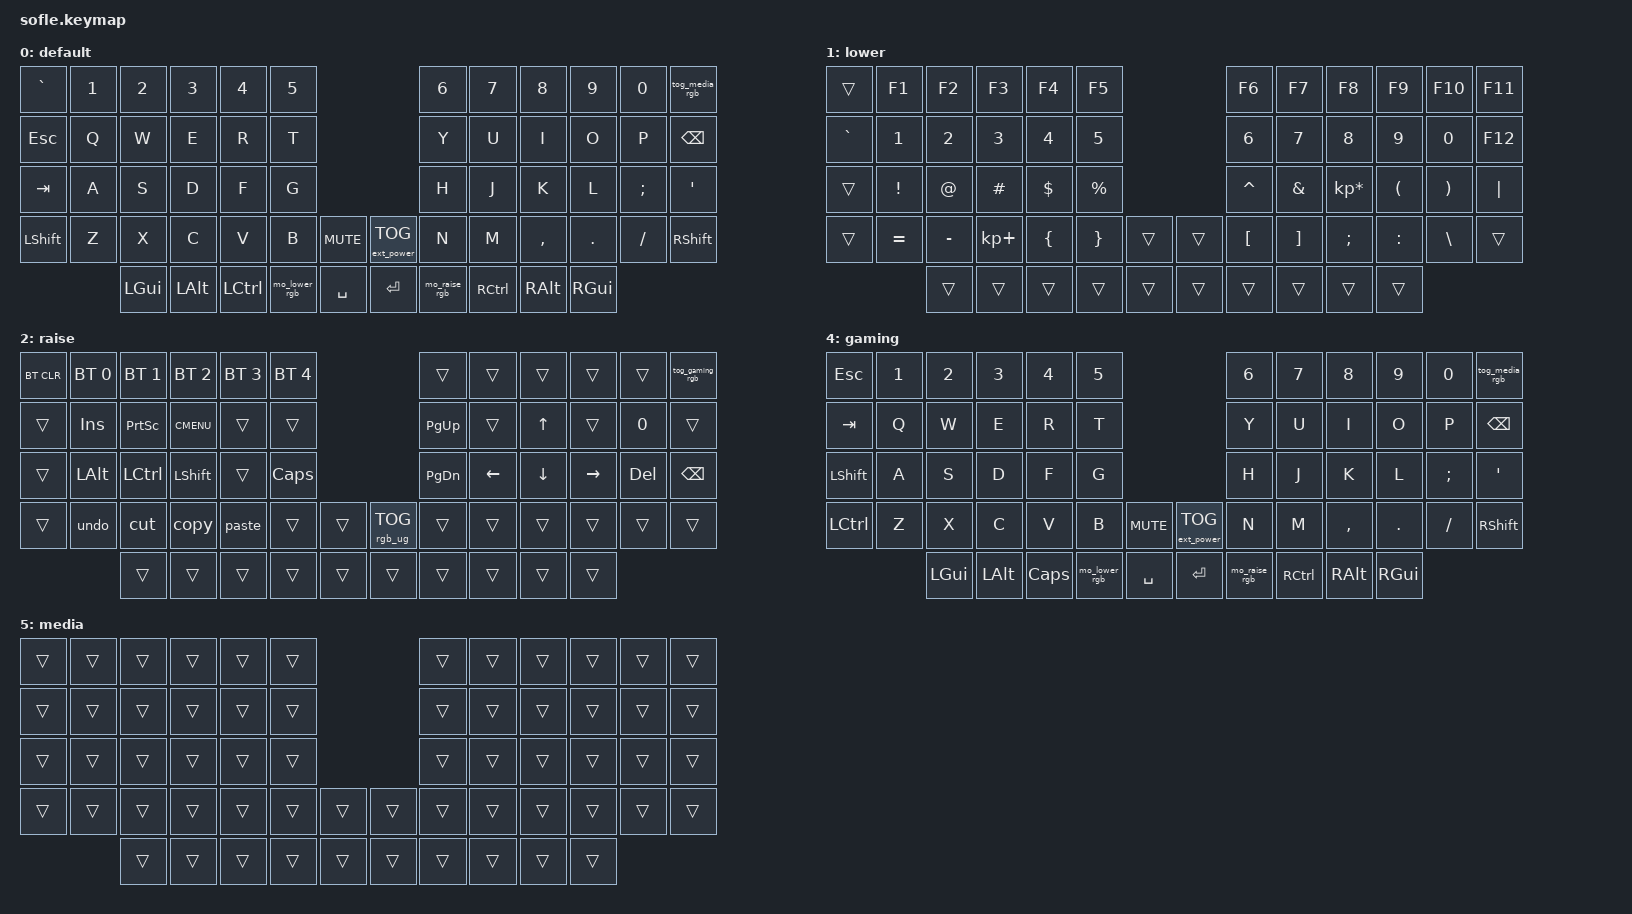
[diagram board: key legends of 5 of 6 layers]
/*
 * Copyright (c) 2020 The ZMK Contributors
 * SPDX-License-Identifier: MIT
 */

/* ===== Includes ===== */
#include <behaviors.dtsi>
#include <dt-bindings/zmk/keys.h>
#include <dt-bindings/zmk/bt.h>
#include <dt-bindings/zmk/ext_power.h>
#include <dt-bindings/zmk/rgb.h>
#include <dt-bindings/led/led.h>

/* ===== Behaviors ===== */
/ {
    macros {
        // Macro: Momentary LOWER layer with RGB hue shift
        mo_lower_rgb: mo_lower_rgb {
            compatible = "zmk,behavior-macro";
            #binding-cells = <0>;
            wait-ms = <0>;
            tap-ms = <0>;
            bindings
                = <&macro_press &mo 1>
                , <&macro_tap &rgb_ug RGB_HUI>  // Single hue shift on press
                , <&macro_pause_for_release>
                , <&macro_release &mo 1>
                , <&macro_tap &rgb_ug RGB_HUD>  // Single hue shift back on release
                ;
        };
        
        // Macro: Momentary RAISE layer with RGB hue shift
        mo_raise_rgb: mo_raise_rgb {
            compatible = "zmk,behavior-macro";
            #binding-cells = <0>;
            wait-ms = <0>;
            tap-ms = <0>;
            bindings
                = <&macro_press &mo 2>
                , <&macro_tap &rgb_ug RGB_HUD>  // Single hue shift on press
                , <&macro_pause_for_release>
                , <&macro_release &mo 2>
                , <&macro_tap &rgb_ug RGB_HUI>  // Single hue shift back on release
                ;
        };
        
        // Macro: Toggle GAMING layer with green RGB color
        // Sets green when entering gaming mode, returns to previous color when exiting
        tog_gaming_rgb: tog_gaming_rgb {
            compatible = "zmk,behavior-macro";
            #binding-cells = <0>;
            wait-ms = <0>;
            tap-ms = <0>;
            bindings
                = <&macro_tap &tog 4>
                , <&macro_tap &rgb_ug RGB_COLOR_HSB(120,100,50)>  // Set green color (120° hue, full saturation, medium brightness)
                ;
        };
        
        // Macro: ADJUST layer with RGB shift (double hue down when active)
        mo_adjust_rgb: mo_adjust_rgb {
            compatible = "zmk,behavior-macro";
            #binding-cells = <0>;
            wait-ms = <0>;
            tap-ms = <0>;
            bindings
                = <&macro_press &mo 3>
                , <&macro_tap &rgb_ug RGB_HUD &rgb_ug RGB_HUD>  // Double hue down shift on press
                , <&macro_pause_for_release>
                , <&macro_release &mo 3>
                , <&macro_tap &rgb_ug RGB_HUI &rgb_ug RGB_HUI>  // Double hue up shift back on release
                ;
        };
        
        // Macro: Toggle MEDIA layer without RGB interference
        // This prevents color shifts from getting stuck when toggling media mode
        tog_media_rgb: tog_media_rgb {
            compatible = "zmk,behavior-macro";
            #binding-cells = <0>;
            wait-ms = <0>;
            tap-ms = <0>;
            bindings
                = <&macro_tap &tog 5>  // Toggle MEDIA layer (no RGB shift to avoid interference)
                ;
        };
        
        // Macro: Undo (Ctrl+Z)
        undo: undo {
            compatible = "zmk,behavior-macro";
            #binding-cells = <0>;
            wait-ms = <30>;
            tap-ms = <30>;
            bindings = <&macro_press &kp LCTRL>, <&macro_tap &kp Z>, <&macro_release &kp LCTRL>;
        };
        
        // Macro: Cut (Ctrl+X)
        cut: cut {
            compatible = "zmk,behavior-macro";
            #binding-cells = <0>;
            wait-ms = <30>;
            tap-ms = <30>;
            bindings = <&macro_press &kp LCTRL>, <&macro_tap &kp X>, <&macro_release &kp LCTRL>;
        };
        
        // Macro: Copy (Ctrl+C)
        copy: copy {
            compatible = "zmk,behavior-macro";
            #binding-cells = <0>;
            wait-ms = <30>;
            tap-ms = <30>;
            bindings = <&macro_press &kp LCTRL>, <&macro_tap &kp C>, <&macro_release &kp LCTRL>;
        };
        
        // Macro: Paste (Ctrl+V)
        paste: paste {
            compatible = "zmk,behavior-macro";
            #binding-cells = <0>;
            wait-ms = <30>;
            tap-ms = <30>;
            bindings = <&macro_press &kp LCTRL>, <&macro_tap &kp V>, <&macro_release &kp LCTRL>;
        };
        
        // Macro: Track Previous (requires 5 encoder ticks for one skip)
        track_prev: track_prev {
            compatible = "zmk,behavior-macro";
            #binding-cells = <0>;
            wait-ms = <0>;
            tap-ms = <0>;
            bindings = <&kp C_PREV>, <&kp C_PREV>, <&kp C_PREV>, <&kp C_PREV>, <&kp C_PREV>;
        };
        
        // Macro: Track Next (requires 5 encoder ticks for one skip)
        track_next: track_next {
            compatible = "zmk,behavior-macro";
            #binding-cells = <0>;
            wait-ms = <0>;
            tap-ms = <0>;
            bindings = <&kp C_NEXT>, <&kp C_NEXT>, <&kp C_NEXT>, <&kp C_NEXT>, <&kp C_NEXT>;
        };
    };
};

/* ===== Layer IDs ===== */
#define BASE    0
#define LOWER   1
#define RAISE   2
#define ADJUST  3
#define GAMING  4
#define MEDIA   5   /* Media control layer for encoders */

/* ===== Readability Macros ===== */
#define TR            &trans
#define NO            &none
#define MO_LOWER      &mo_lower_rgb   /* Momentary LOWER with RGB hue shift */
#define MO_RAISE      &mo_raise_rgb   /* Momentary RAISE with RGB hue shift */
#define TG_GAMING     &tog_gaming_rgb /* Toggle GAMING with RGB hue shift */
#define TG_MEDIA      &tog_media_rgb  /* Toggle MEDIA encoder layer */
// Standard encoder bindings - 1:1 response with EC11 encoders (20 pulses per rotation)
#define SENS_BINDINGS &inc_dec_kp LEFT RIGHT &inc_dec_kp DOWN UP  // Left encoder: horizontal (1:1), Right encoder: vertical (1:1, inverted for natural scroll)
#define MEDIA_SENS    &inc_dec_kp C_VOL_DN C_VOL_UP &inc_dec_kp C_PREV C_NEXT  // Left encoder: volume (1:1), Right encoder: track skip (1:1 per tick, but requires 5 ticks for intentional skip)

/* ===== RGB Layer Colors ===== */
// These macros shift RGB hue when layers are activated:
// Base layer:   Default RGB color (neutral)
// Lower layer:  Hue +2 steps (slight shift)
// Raise layer:  Hue +4 steps (different shift)
// Gaming layer: Hue +6 steps (distinct shift)
// Note: Adjust layer activates with LOWER+RAISE, so it inherits their combined shifts

/*
 * Temporarily here because nice nano v2 spi is not defined on ZMK Yet
 * Source: https://github.com/zmkfirmware/zmk/blob/main/app/boards/shields/reviung41/boards/nice_nano.overlay
 * GitHub Issue: https://github.com/zmkfirmware/zmk/issues/885
 */

/* ===== SPI / WS2812 Underglow ===== */
&pinctrl {
    spi3_default: spi3_default {
        group1 { psels = <NRF_PSEL(SPIM_MOSI, 0, 8)>; };
    };
    spi3_sleep: spi3_sleep {
        group1 {
            psels = <NRF_PSEL(SPIM_MOSI, 0, 8)>;
            low-power-enable;
        };
    };
};

&sensors {
    left_config {
        triggers-per-rotation = <50>;  // Doubled for immediate response (2 pulses per detent)
    };

    right_config {
        triggers-per-rotation = <50>;  // Doubled for immediate response (2 pulses per detent)
    };
};

&spi3 {
    compatible = "nordic,nrf-spim";
    status = "okay";
    pinctrl-0 = <&spi3_default>;
    pinctrl-1 = <&spi3_sleep>;
    pinctrl-names = "default", "sleep";

    led_strip: ws2812@0 {
        compatible = "worldsemi,ws2812-spi";
        label = "WS2812";

        /* SPI */
        reg = <0>; /* ignored, but necessary for SPI bindings */
        spi-max-frequency = <4000000>;

        /* WS2812 */
        chain-length   = <30>;
        spi-one-frame  = <0x70>;
        spi-zero-frame = <0x40>;
        color-mapping  = <LED_COLOR_ID_GREEN LED_COLOR_ID_RED LED_COLOR_ID_BLUE>;
    };
};

 / {
    chosen { zmk,underglow = &led_strip; };
 };

/* ===== Conditional Layers ===== */
 / {
    conditional_layers {
        compatible = "zmk,conditional-layers";
        adjust_layer {
            if-layers  = <LOWER RAISE>;
            then-layer = <ADJUST>;
        };
    };

    /* ===== Keymap ===== */
    keymap {
        compatible = "zmk,keymap";

        /* ---------- BASE (default) ---------- */
        default_layer {
            label = "default";
            // ┌──────┬─────┬─────┬─────┬─────┬─────┐                         ┌─────┬─────┬─────┬─────┬─────┬────────┐
            // │  `   │  1  │  2  │  3  │  4  │  5  │                         │  6  │  7  │  8  │  9  │  0  │MD_TOG  │  <-- above BKSP
            // │ ESC  │  Q  │  W  │  E  │  R  │  T  │                         │  Y  │  U  │  I  │  O  │  P  │ BKSP   │
            // │ TAB  │  A  │  S  │  D  │  F  │  G  │                         │  H  │  J  │  K  │  L  │  ;  │  '     │
            // │ SHIFT│  Z  │  X  │  C  │  V  │  B  │  MUTE  │      │ EXTPWR │  N  │  M  │  ,  │  .  │  /  │ SHIFT  │
            // └──────┴─────┴─────┴─────┴─────┴─────┴────────┴──────┴────────┴─────┴─────┴─────┴─────┴─────┴────────┘
            //                   │ GUI │ ALT │ CTRL│ LOWER│ SPACE│    │ ENTER│ RAISE│ CTRL│ ALT │ GUI │
            bindings = <
                &kp GRAVE &kp N1    &kp N2    &kp N3    &kp N4    &kp N5                            &kp N6   &kp N7    &kp N8    &kp N9    &kp N0    TG_MEDIA
                &kp ESC   &kp Q     &kp W     &kp E     &kp R     &kp T                             &kp Y    &kp U     &kp I     &kp O     &kp P     &kp BSPC
                &kp TAB   &kp A     &kp S     &kp D     &kp F     &kp G                             &kp H    &kp J     &kp K     &kp L     &kp SEMI  &kp SQT
                &kp LSHFT &kp Z     &kp X     &kp C     &kp V     &kp B   &kp C_MUTE &ext_power EP_TOG  &kp N &kp M     &kp COMMA &kp DOT   &kp FSLH  &kp RSHFT
                                   &kp LGUI &kp LALT &kp LCTRL MO_LOWER &kp SPACE       &kp RET     MO_RAISE &kp RCTRL &kp RALT &kp RGUI
            >;
            sensor-bindings = < SENS_BINDINGS >;
        };

        /* ---------- LOWER ---------- */
        lower_layer {
            label = "lower";
            // ┌──────┬─────┬─────┬─────┬─────┬─────┐                         ┌─────┬─────┬─────┬─────┬─────┬────────┐
            // │  TR  │ F1  │ F2  │ F3  │ F4  │ F5  │                         │ F6  │ F7  │ F8  │ F9  │ F10 │  F11   │
            // │  `   │  1  │  2  │  3  │  4  │  5  │                         │  6  │  7  │  8  │  9  │  0  │  F12   │
            // │  TR  │  !  │  @  │  #  │  $  │  %  │                         │  ^  │  &  │  *  │  (  │  )  │  |     │
            // │  TR  │  =  │  -  │  +  │  {  │  }  │   TR   │      │   TR   │  [  │  ]  │  ;  │  :  │  \  │   TR   │
            // └──────┴─────┴─────┴─────┴─────┴─────┴────────┴──────┴────────┴─────┴─────┴─────┴─────┴─────┴────────┘
            //                   │ TR  │ TR  │ TR  │  TR  │  TR  │    │  TR  │  TR  │ TR  │ TR  │ TR  │
            bindings = <
                TR        &kp F1     &kp F2     &kp F3         &kp F4     &kp F5              &kp F6     &kp F7     &kp F8          &kp F9     &kp F10    &kp F11
                &kp GRAVE &kp N1     &kp N2     &kp N3         &kp N4     &kp N5              &kp N6     &kp N7     &kp N8          &kp N9     &kp N0     &kp F12
                TR        &kp EXCL   &kp AT     &kp HASH       &kp DLLR   &kp PRCNT           &kp CARET  &kp AMPS   &kp KP_MULTIPLY &kp LPAR   &kp RPAR   &kp PIPE
                TR        &kp EQUAL  &kp MINUS  &kp KP_PLUS    &kp LBRC   &kp RBRC    TR  TR  &kp LBKT   &kp RBKT   &kp SEMI        &kp COLON  &kp BSLH   TR
                                   TR          TR             TR         TR         TR   TR  TR          TR          TR              TR
            >;
            sensor-bindings = < SENS_BINDINGS >;
        };

        /* ---------- RAISE ---------- */
        raise_layer {
            label = "raise";
            // ┌────────┬─────┬─────┬─────┬─────┬─────┐                         ┌─────┬─────┬─────┬─────┬─────┬────────┐
            // │ BT_CLR │ BT0 │ BT1 │ BT2 │ BT3 │ BT4 │                         │ TR  │ TR  │ TR  │ TR  │ TR  │ GM_TOG │
            // │   TR   │ INS │PSCRN│MENU │ TR  │ TR  │                         │PG_UP│ TR  │ UP  │ TR  │  0  │   TR   │
            // │   TR   │ ALT │CTRL │SHIFT│ TR  │CAPS │                         │PG_DN│LEFT │DOWN │RIGHT│ DEL │  BKSP  │
            // │   TR   │UNDO │ CUT │COPY │PASTE│ TR  │   TR   │      │RGB_TOG │ TR  │ TR  │ TR  │ TR  │ TR  │   TR   │
            // └────────┴─────┴─────┴─────┴─────┴─────┴────────┴──────┴────────┴─────┴─────┴─────┴─────┴─────┴────────┘
            //                   │ TR  │ TR  │ TR  │  TR  │  TR  │    │  TR  │  TR  │ TR  │ TR  │ TR  │
            bindings = <
                &bt BT_CLR  &bt BT_SEL 0 &bt BT_SEL 1 &bt BT_SEL 2 &bt BT_SEL 3 &bt BT_SEL 4            TR        TR        TR        TR        TR       TG_GAMING
                TR          &kp INS      &kp PSCRN    &kp K_CMENU  TR            TR                      &kp PG_UP TR        &kp UP    TR        &kp N0   TR
                TR          &kp LALT     &kp LCTRL    &kp LSHFT    TR            &kp CLCK                 &kp PG_DN &kp LEFT  &kp DOWN  &kp RIGHT &kp DEL  &kp BSPC
                TR          &undo        &cut         &copy        &paste        TR       TR   &rgb_ug RGB_TOG   TR        TR        TR        TR       TR       TR
                                             TR            TR           TR        TR       TR   TR       TR        TR        TR        TR
            >;
            sensor-bindings = < SENS_BINDINGS >;
        };

        /* ---------- ADJUST (auto when LOWER+RAISE) ---------- */
        adjust_layer {
            label = "adjust";
            // ┌────────┬─────┬─────┬─────┬─────┬─────┐                         ┌─────┬─────┬─────┬─────┬─────┬────────┐
            // │ BT_CLR │ BT0 │ BT1 │ BT2 │ BT3 │ BT4 │                         │ TR  │ TR  │ TR  │ TR  │ TR  │   TR   │
            // │ EP_TOG │HUE -│HUE +│SAT -│SAT +│ EFF │                         │ TR  │ TR  │ TR  │ TR  │ TR  │   TR   │
            // │   TR   │BRI -│BRI +│ TR  │ TR  │ TR  │                         │ TR  │ TR  │ TR  │ TR  │ TR  │   TR   │
            // │   TR   │ TR  │ TR  │ TR  │ TR  │ TR  │   TR   │      │RGB_TOG │ TR  │ TR  │ TR  │ TR  │ TR  │   TR   │
            // └────────┴─────┴─────┴─────┴─────┴─────┴────────┴──────┴────────┴─────┴─────┴─────┴─────┴─────┴────────┘
            //                   │ TR  │ TR  │ TR  │  TR  │  TR  │    │  TR  │  TR  │ TR  │ TR  │ TR  │
            bindings = <
                &bt BT_CLR        &bt BT_SEL 0     &bt BT_SEL 1     &bt BT_SEL 2     &bt BT_SEL 3     &bt BT_SEL 4                         TR   TR   TR   TR   TR   TR
                &ext_power EP_TOG &rgb_ug RGB_HUD  &rgb_ug RGB_HUI  &rgb_ug RGB_SAD  &rgb_ug RGB_SAI  &rgb_ug RGB_EFF                      TR   TR   TR   TR   TR   TR
                TR                &rgb_ug RGB_BRD  &rgb_ug RGB_BRI  TR                TR                TR                                   TR   TR   TR   TR   TR   TR
                TR                TR               TR               TR                TR                TR                &rgb_ug RGB_TOG  TR   TR   TR   TR   TR   TR
                                                 TR               TR               TR               TR               TR               TR   TR   TR   TR   TR
            >;
        };

        /* ---------- GAMING (toggle via RAISE layer) ---------- */
        gaming_layer {
            label = "gaming";
            // ┌──────┬─────┬─────┬─────┬─────┬─────┐                         ┌─────┬─────┬─────┬─────┬─────┬────────┐
            // │ ESC  │  1  │  2  │  3  │  4  │  5  │                         │  6  │  7  │  8  │  9  │  0  │ GM_TOG │  <-- exit gaming
            // │ TAB  │  Q  │  W  │  E  │  R  │  T  │                         │  Y  │  U  │  I  │  O  │  P  │  BKSP  │
            // │SHIFT │  A  │  S  │  D  │  F  │  G  │                         │  H  │  J  │  K  │  L  │  ;  │   '    │
            // │ CTRL │  Z  │  X  │  C  │  V  │  B  │  MUTE  │      │ EXTPWR │  N  │  M  │  ,  │  .  │  /  │ SHIFT  │
            // └──────┴─────┴─────┴─────┴─────┴─────┴────────┴──────┴────────┴─────┴─────┴─────┴─────┴─────┴────────┘
            //                   │ GUI │ ALT │CAPS │LOWER │SPACE │    │ENTER │RAISE │CTRL │ ALT │ GUI │
            bindings = <
                &kp ESC &kp N1    &kp N2    &kp N3    &kp N4    &kp N5                            &kp N6   &kp N7    &kp N8    &kp N9    &kp N0    TG_MEDIA
                &kp TAB   &kp Q     &kp W     &kp E     &kp R     &kp T                             &kp Y    &kp U     &kp I     &kp O     &kp P     &kp BSPC
                &kp LSHFT   &kp A     &kp S     &kp D     &kp F     &kp G                             &kp H    &kp J     &kp K     &kp L     &kp SEMI  &kp SQT
                &kp LCTRL &kp Z     &kp X     &kp C     &kp V     &kp B   &kp C_MUTE &ext_power EP_TOG  &kp N &kp M     &kp COMMA &kp DOT   &kp FSLH  &kp RSHFT
                                   &kp LGUI &kp LALT &kp CLCK MO_LOWER &kp SPACE       &kp RET     MO_RAISE &kp RCTRL &kp RALT &kp RGUI
            >;
            sensor-bindings = < SENS_BINDINGS >;
        };

        /* ---------- MEDIA (encoder-only layer for media controls) ---------- */
        media_layer {
            label = "media";
            // ┌──────┬─────┬─────┬─────┬─────┬─────┐                         ┌─────┬─────┬─────┬─────┬─────┬────────┐
            // │  TR  │ TR  │ TR  │ TR  │ TR  │ TR  │                         │ TR  │ TR  │ TR  │ TR  │ TR  │   TR   │
            // │  TR  │ TR  │ TR  │ TR  │ TR  │ TR  │                         │ TR  │ TR  │ TR  │ TR  │ TR  │   TR   │
            // │  TR  │ TR  │ TR  │ TR  │ TR  │ TR  │                         │ TR  │ TR  │ TR  │ TR  │ TR  │   TR   │
            // │  TR  │ TR  │ TR  │ TR  │ TR  │ TR  │   TR   │      │   TR   │ TR  │ TR  │ TR  │ TR  │ TR  │   TR   │
            // └──────┴─────┴─────┴─────┴─────┴─────┴────────┴──────┴────────┴─────┴─────┴─────┴─────┴─────┴────────┘
            //                   │ TR  │ TR  │ TR  │  TR  │  TR  │    │  TR  │  TR  │ TR  │ TR  │ TR  │
            // Left Encoder: Volume Down/Up  |  Right Encoder: Previous/Next Track
            bindings = <
                TR TR TR TR TR TR             TR TR TR TR TR TR
                TR TR TR TR TR TR             TR TR TR TR TR TR
                TR TR TR TR TR TR             TR TR TR TR TR TR
                TR TR TR TR TR TR TR TR       TR TR TR TR TR TR
                         TR TR TR TR TR TR    TR TR TR TR
            >;
            sensor-bindings = < MEDIA_SENS >;  // Volume & track controls
        };
    };
};
